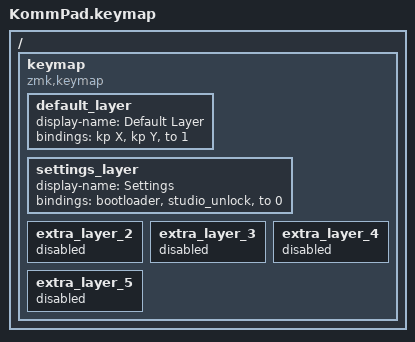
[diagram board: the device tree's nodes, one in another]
/*
 * Copyright (c) 2022 The ZMK Contributors
 *
 * SPDX-License-Identifier: MIT
 */

#include <behaviors.dtsi>
#include <dt-bindings/zmk/keys.h>
#include <dt-bindings/zmk/bt.h>

/ {
    keymap {
        compatible = "zmk,keymap";

        default_layer {
            display-name = "Default Layer";
            bindings = <
                &kp X  
                &kp Y  
                &to 1   
            >;
        };
        settings_layer {
            display-name = "Settings";
            bindings = <
                &bootloader       
                &studio_unlock       
                &to 0
            >;
        };

        extra_layer_2 {
            status = "reserved";
        };

        extra_layer_3 {
            status = "reserved";
        };

        extra_layer_4 {
            status = "reserved";
        };
        
        extra_layer_5 {
            status = "reserved";
        };
    };
};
